# STM32L4x9 register map
File version: 1.4
Registers are 32-bit, read-write, reset 0x0 unless marked. A register's access mark holds for its fields unless they carry their own. Offsets are from the block's base; [hi:lo] are bit positions; {n}, {i} and the like mark numbered series.

## DBGMCU — Debug support
Base 0xE0042000
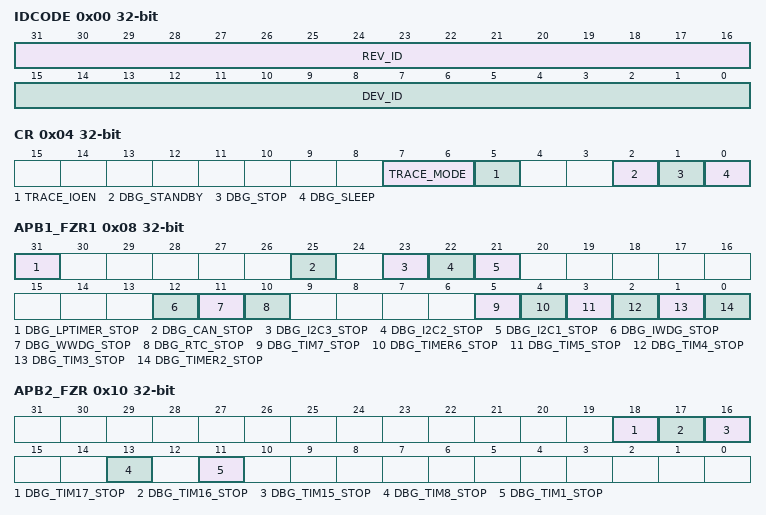
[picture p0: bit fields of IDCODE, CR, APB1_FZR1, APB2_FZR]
0x00 IDCODE ro — MCU Device ID Code Register
  [31:16] REV_ID — Revision Identifier
  [15:0] DEV_ID — Device Identifier
0x04 CR — Debug MCU Configuration Register
  [7:6] TRACE_MODE — Trace pin assignment control
  [5] TRACE_IOEN — Trace pin assignment control
  [2] DBG_STANDBY — Debug Standby Mode
  [1] DBG_STOP — Debug Stop Mode
  [0] DBG_SLEEP — Debug Sleep Mode
0x08 APB1_FZR1 — APB Low Freeze Register 1
  [31] DBG_LPTIMER_STOP — LPTIM1 counter stopped when core is halted
  [25] DBG_CAN_STOP — bxCAN stopped when core is halted
  [23] DBG_I2C3_STOP — I2C3 SMBUS timeout counter stopped when core is halted
  [22] DBG_I2C2_STOP — I2C2 SMBUS timeout mode stopped when core is halted
  [21] DBG_I2C1_STOP — I2C1 SMBUS timeout mode stopped when core is halted
  [12] DBG_IWDG_STOP — Debug Independent Wachdog stopped when Core is halted
  [11] DBG_WWDG_STOP — Debug Window Wachdog stopped when Core is halted
  [10] DBG_RTC_STOP — Debug RTC stopped when Core is halted
  [5] DBG_TIM7_STOP — TIM7 counter stopped when core is halted
  [4] DBG_TIMER6_STOP — Debug Timer 6 stopped when Core is halted
  [3] DBG_TIM5_STOP — TIM5 counter stopped when core is halted
  [2] DBG_TIM4_STOP — TIM4 counter stopped when core is halted
  [1] DBG_TIM3_STOP — TIM3 counter stopped when core is halted
  [0] DBG_TIMER2_STOP — Debug Timer 2 stopped when Core is halted
0x0C APB1_FZR2 — APB Low Freeze Register 2
  [5] DBG_LPTIM2_STOP — LPTIM2 counter stopped when core is halted
0x10 APB2_FZR — APB High Freeze Register
  [18] DBG_TIM17_STOP — TIM17 counter stopped when core is halted
  [17] DBG_TIM16_STOP — TIM16 counter stopped when core is halted
  [16] DBG_TIM15_STOP — TIM15 counter stopped when core is halted
  [13] DBG_TIM8_STOP — TIM8 counter stopped when core is halted
  [11] DBG_TIM1_STOP — TIM1 counter stopped when core is halted

## PWR — Power control
Base 0x40007000
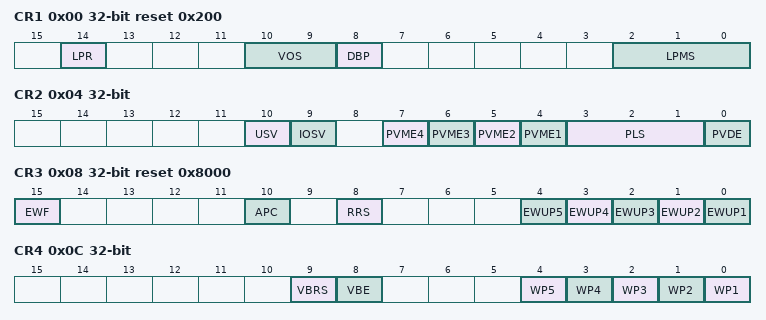
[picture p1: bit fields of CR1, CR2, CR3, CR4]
0x00 CR1 reset 0x200 — Power control register 1
  [14] LPR — Low-power run
  [10:9] VOS — Voltage scaling range selection
  [8] DBP — Disable backup domain write protection
  [2:0] LPMS — Low-power mode selection
0x04 CR2 — Power control register 2
  [10] USV — VDDUSB USB supply valid
  [9] IOSV — VDDIO2 Independent I/Os supply valid
  [7] PVME4 — Peripheral voltage monitoring 4 enable: VDDA vs. 2.2V
  [6] PVME3 — Peripheral voltage monitoring 3 enable: VDDA vs. 1.62V
  [5] PVME2 — Peripheral voltage monitoring 2 enable: VDDIO2 vs. 0.9V
  [4] PVME1 — Peripheral voltage monitoring 1 enable: VDDUSB vs. 1.2V
  [3:1] PLS — Power voltage detector level selection
  [0] PVDE — Power voltage detector enable
0x08 CR3 reset 0x8000 — Power control register 3
  [15] EWF — Enable internal wakeup line
  [10] APC — Apply pull-up and pull-down configuration
  [8] RRS — SRAM2 retention in Standby mode
  [n-1] EWUP{n} (n=1..5) — Enable Wakeup pin WKUP{n}
0x0C CR4 — Power control register 4
  [9] VBRS — VBAT battery charging resistor selection
  [8] VBE — VBAT battery charging enable
  [n-1] WP{n} (n=1..5) — Wakeup pin WKUP{n} polarity
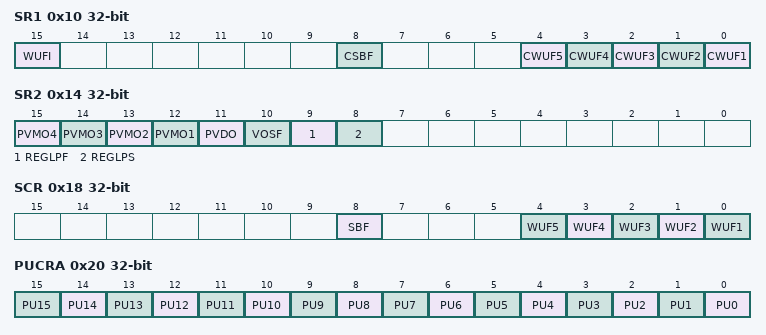
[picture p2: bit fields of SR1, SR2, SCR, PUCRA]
0x10 SR1 ro — Power status register 1
  [15] WUFI — Wakeup flag internal
  [8] CSBF — Standby flag
  [n-1] CWUF{n} (n=1..5) — Wakeup flag {n}
0x14 SR2 ro — Power status register 2
  [15] PVMO4 — Peripheral voltage monitoring output: VDDA vs. 2.2 V
  [14] PVMO3 — Peripheral voltage monitoring output: VDDA vs. 1.62 V
  [13] PVMO2 — Peripheral voltage monitoring output: VDDIO2 vs. 0.9 V
  [12] PVMO1 — Peripheral voltage monitoring output: VDDUSB vs. 1.2 V
  [11] PVDO — Power voltage detector output
  [10] VOSF — Voltage scaling flag
  [9] REGLPF — Low-power regulator flag
  [8] REGLPS — Low-power regulator started
0x18 SCR wo — Power status clear register
  [8] SBF — Clear standby flag
  [n-1] WUF{n} (n=1..5) — Clear wakeup flag {n}
0x20 PUCRA — Power Port A pull-up control register
  [n] PU{n} (n=0..15) — Port A pull-up bit y (y=0..15)
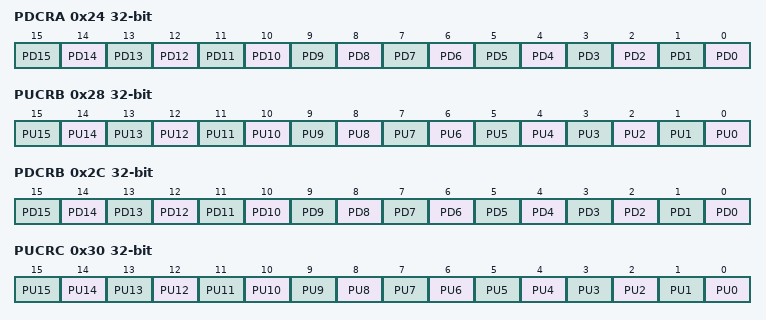
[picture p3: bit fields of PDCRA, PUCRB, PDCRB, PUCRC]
0x24 PDCRA — Power Port A pull-down control register
  [n] PD{n} (n=0..15) — Port A pull-down bit y (y=0..15)
0x28 PUCRB — Power Port B pull-up control register
  [n] PU{n} (n=0..15) — Port B pull-up bit y (y=0..15)
0x2C PDCRB — Power Port B pull-down control register
  [n] PD{n} (n=0..15) — Port B pull-down bit y (y=0..15)
0x30 PUCRC — Power Port C pull-up control register
  [n] PU{n} (n=0..15) — Port C pull-up bit y (y=0..15)
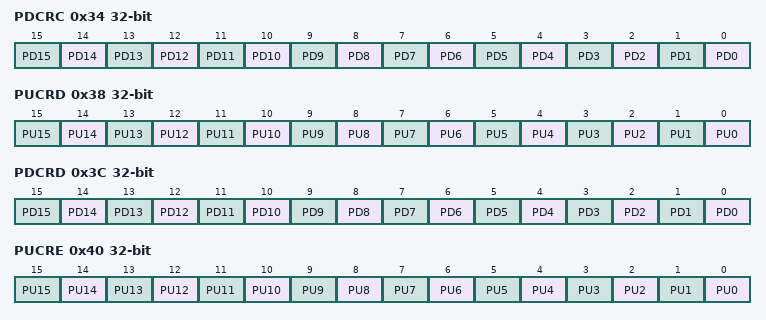
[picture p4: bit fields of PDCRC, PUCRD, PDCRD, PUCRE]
0x34 PDCRC — Power Port C pull-down control register
  [n] PD{n} (n=0..15) — Port C pull-down bit y (y=0..15)
0x38 PUCRD — Power Port D pull-up control register
  [n] PU{n} (n=0..15) — Port D pull-up bit y (y=0..15)
0x3C PDCRD — Power Port D pull-down control register
  [n] PD{n} (n=0..15) — Port D pull-down bit y (y=0..15)
0x40 PUCRE — Power Port E pull-up control register
  [n] PU{n} (n=0..15) — Port E pull-up bit y (y=0..15)
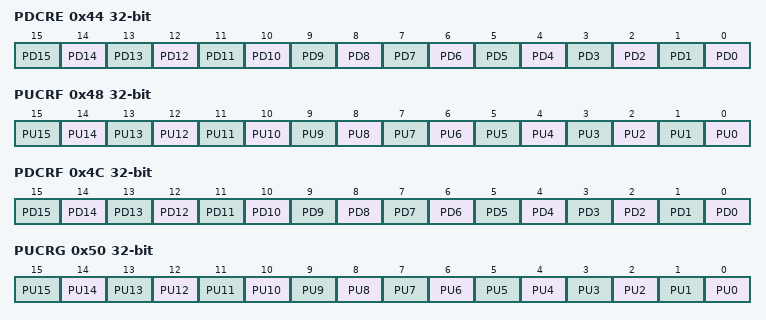
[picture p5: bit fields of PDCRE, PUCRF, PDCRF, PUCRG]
0x44 PDCRE — Power Port E pull-down control register
  [n] PD{n} (n=0..15) — Port E pull-down bit y (y=0..15)
0x48 PUCRF — Power Port F pull-up control register
  [n] PU{n} (n=0..15) — Port F pull-up bit y (y=0..15)
0x4C PDCRF — Power Port F pull-down control register
  [n] PD{n} (n=0..15) — Port F pull-down bit y (y=0..15)
0x50 PUCRG — Power Port G pull-up control register
  [n] PU{n} (n=0..15) — Port G pull-up bit y (y=0..15)
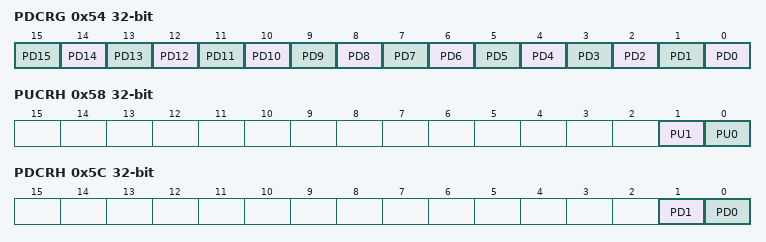
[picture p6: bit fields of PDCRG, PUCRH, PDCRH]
0x54 PDCRG — Power Port G pull-down control register
  [n] PD{n} (n=0..15) — Port G pull-down bit y (y=0..15)
0x58 PUCRH — Power Port H pull-up control register
  [1] PU1 — Port H pull-up bit y (y=0..1)
  [0] PU0 — Port H pull-up bit y (y=0..1)
0x5C PDCRH — Power Port H pull-down control register
  [1] PD1 — Port H pull-down bit y (y=0..1)
  [0] PD0 — Port H pull-down bit y (y=0..1)
